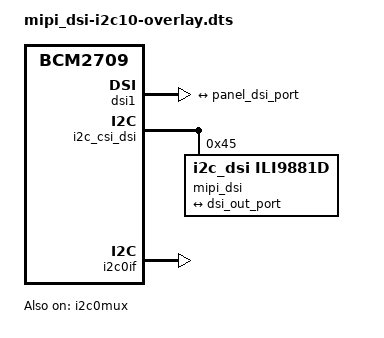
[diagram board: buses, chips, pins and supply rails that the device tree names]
/*
 * Copyright (C) 2020 Seeed Studio
 * Zhangqun Ming <north_sea@qq.com>
 *
 * MIT License
 *
 */
/dts-v1/;
/plugin/;

/ {
	compatible = "brcm,bcm2835", "brcm,bcm2708", "brcm,bcm2709";

	fragment@0 {
		target = <&dsi1>;
		__overlay__ {
			#address-cells = <1>; size-cells = <0>;
			status = "okay";

			port {
				dsi_out_port: endpoint {
					remote-endpoint = <&panel_dsi_port>;
				};
			};
		};
	};

	fragment@1 {
		target = <&i2c_csi_dsi>;
		__overlay__ {
			#address-cells = <1>;
			#size-cells = <0>;
			status = "okay";
			mipi_dsi@45 {
				//compatible = "i2c_dsi,st7701s";
				compatible = "i2c_dsi,ili9881d";
				reg = <0x45>;
				port {
					panel_dsi_port: endpoint {
						remote-endpoint = <&dsi_out_port>;
					};
				};
			};
		};
	};
	
	fragment@2 {
		target = <&i2c0if>;
		__overlay__ {
			status = "okay";
		};
	};

	fragment@3 {
		target = <&i2c0mux>;
		__overlay__ {
			status = "okay";
		};
	};
};
